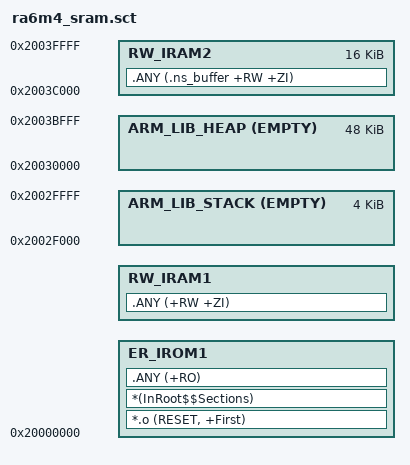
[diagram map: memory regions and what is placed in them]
;***************************************************************
;* RA6M4 linker scatter file (running code from internal SRAM) *
;***************************************************************

LR_IROM1 0x20000000 0x40000
{
   ER_IROM1 0x20000000
   {
      *.o (RESET, +First)
      *(InRoot$$Sections)
      .ANY (+RO)
   }
   
   RW_IRAM1 +0
   { 
      .ANY (+RW +ZI)
   }
   
   ScatterAssert((ImageLength(ER_IROM1) + ImageLength(RW_IRAM1)) < 0x2F000)
   
   ARM_LIB_STACK 0x20030000 EMPTY -0x1000
   {
   }
   
   ARM_LIB_HEAP 0x20030000 EMPTY 0xC000
   {
   }
   
   RW_IRAM2 0x2003C000 0x4000
   {
      .ANY (.ns_buffer +RW +ZI)
   }
}
